# R7FA8M1AH register map
Vendor: Renesas; Series: RA8; File version: 1.2
CPU: CM85 r0p0, little endian, MPU, FPU, VTOR, 4 interrupt priority bits
Registers are 32-bit, read-write, reset 0x0 unless marked. A register's access mark holds for its fields unless they carry their own. Offsets are from the block's base; [hi:lo] are bit positions; {n}, {i} and the like mark numbered series; 'fields as' and 'values as' point back to an identical list.

## GLCDC — Graphics LCD Controller
Base 0x40342000
Same registers: GLCDC_NS 0x50342000
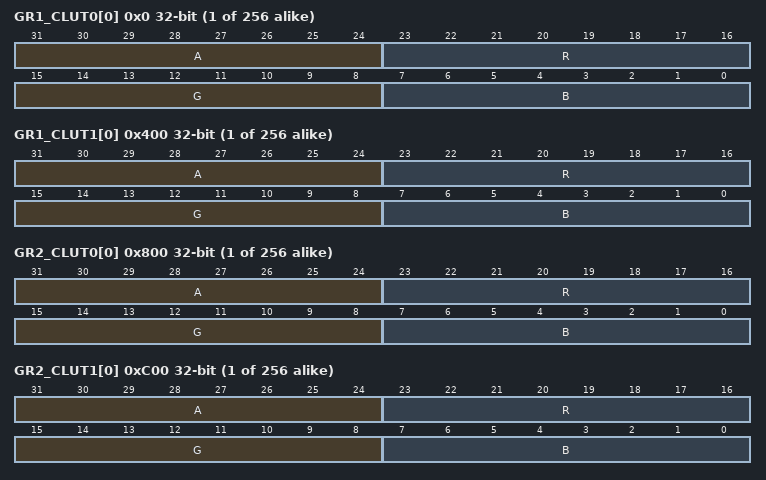
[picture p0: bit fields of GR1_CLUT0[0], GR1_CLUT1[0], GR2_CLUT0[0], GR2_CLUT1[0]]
{0x0+4i} GR1_CLUT0[{i}] (i=0..255) reset not defined — Color Palette 0 Plane for Graphics 1 Plane
  [31:24] A — Alpha Blending Value of Color Palette n Plane for Graphics m Plane
  [23:16] R — R Value of Color Palette n Plane for Graphics m Plane
  [15:8] G — G Value of Color Palette n Plane for Graphics m Plane
  [7:0] B — B Value of Color Palette n Plane for Graphics m Plane
{0x400+4i} GR1_CLUT1[{i}] (i=0..255) reset not defined — Color Palette 1 Plane for Graphics 1 Plane
  fields as GR1_CLUT0[0]
{0x800+4i} GR2_CLUT0[{i}] (i=0..255) reset not defined — Color Palette 0 Plane for Graphics 2 Plane
  fields as GR1_CLUT0[0]
{0xC00+4i} GR2_CLUT1[{i}] (i=0..255) reset not defined — Color Palette 1 Plane for Graphics 2 Plane
  fields as GR1_CLUT0[0]
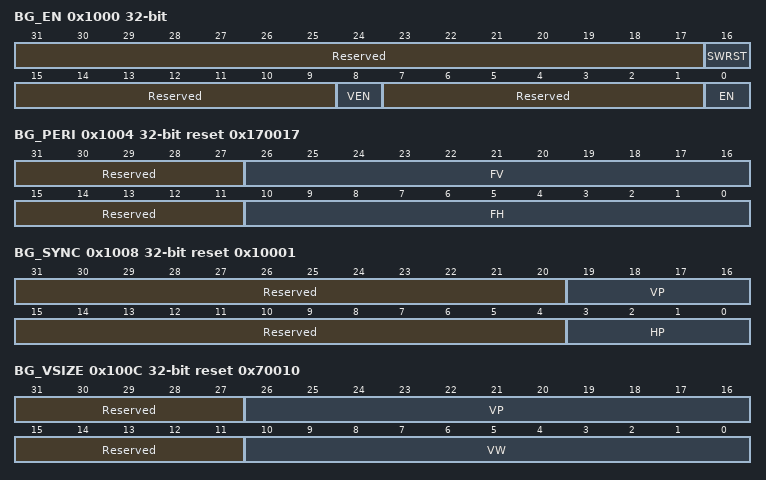
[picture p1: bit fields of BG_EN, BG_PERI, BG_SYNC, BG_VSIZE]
0x1000 BG_EN — Background Plane Setting Operation Control Register
  [31:17] Reserved — These bits are read as 000000000000000. The write value should be 000000000000000.
  [16] SWRST — Entire module SW reset control
    1=Releases the entire module from the SW reset state; 0=Places the entire module in the SW reset state
  [15:9] Reserved — These bits are read as 0000000. The write value should be 0000000.
  [8] VEN write-1-sets read-modifies — Control of LCDC internal register value reflection to internal operations
    1=Enables; 0=Disables(Cleared to 0 by an internal source)
  [7:1] Reserved — These bits are read as 0000000. The write value should be 0000000.
  [0] EN — Background plane generation module operation enable
    1=Enables operation; 0=Disables operation
0x1004 BG_PERI reset 0x170017 — Background Plane Setting Free-Running Period Register
  [31:27] Reserved — These bits are read as 00000. The write value should be 00000.
  [26:16] FV range 0x013..0x3FF — Background plane vertical synchronization signal period on the basis of line.
    other=FV (FV lines.The valid range is 0x013 to 0x3FF.)
  [15:11] Reserved — These bits are read as 00000. The write value should be 00000.
  [10:0] FH range 0x017..0x3FF — Background plane horizontal synchronization signal period on the basis of pixel clock (PXCLK).
    other=FH (FH lines. The valid range is 0x017 to 0x3FF.)
0x1008 BG_SYNC reset 0x10001 — Background Plane Setting Synchronization Position Register
  [31:20] Reserved — These bits are read as 000000000000. The write value should be 000000000000.
  [19:16] VP — Background plane vertical synchronization signal assertion position on the basis of line.
    0=Setting prohibited; other=others ((VP)th line)
  [15:4] Reserved — These bits are read as 000000000000. The write value should be 000000000000.
  [3:0] HP — Background plane horizontal synchronization signal assertion position on the basis of pixel clock (PXCLK).
    0=Setting prohibited; other=others ((HP)th line (pixels))
0x100C BG_VSIZE reset 0x70010 — Background Plane Setting Full Image Vertical Size Register
  [31:27] Reserved — These bits are read as 00000. The write value should be 00000.
  [26:16] VP range 0x0003..0x3EF — Background plane vertical valid pixel start position on the basis of line
    other=VP (VP lines. The valid range is 0x003 to 0x3EF.)
  [15:11] Reserved — These bits are read as 00000. The write value should be 00000.
  [10:0] VW range 0x0010..0x03FC — Background plane vertical valid pixel width on the basis of line
    other=VW (VW lines. The valid range is 0x010 to 0x3F0.)
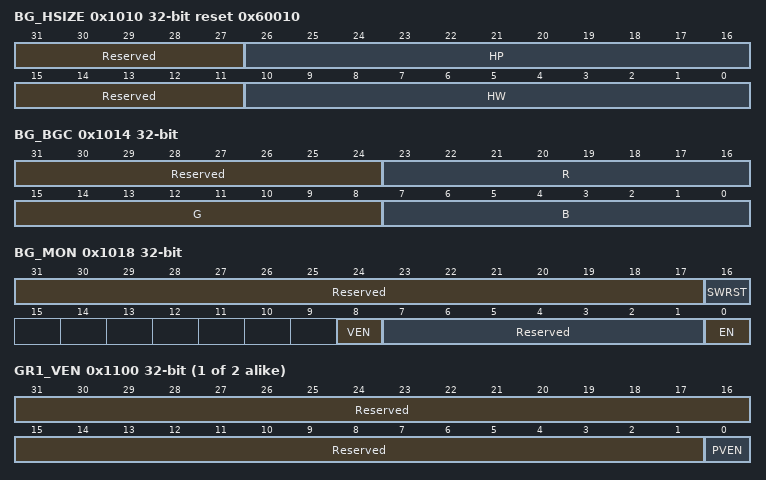
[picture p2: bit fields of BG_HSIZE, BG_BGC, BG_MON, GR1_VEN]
0x1010 BG_HSIZE reset 0x60010 — Background Plane Setting Full Image Horizontal Size Register
  [31:27] Reserved — These bits are read as 00000. The write value should be 00000.
  [26:16] HP range 0x006..0x3EE — Background plane horizontal valid pixel start position on the basis of pixel clock (PXCLK).
    other=HP (HP cycle(pixel). The valid range is 0x006 to 0x3EE.)
  [15:11] Reserved — These bits are read as 00000. The write value should be 00000.
  [10:0] HW range 0x010..0x3F8 — Background plane horizontall valid pixel width on the basis of pixel clock (PXCLK)Note: When serial RGB is selected as the output format for the output control block, add two to the horizontal enable signal width and set the resulting value to this field.
    other=HW (HW cycles. The valid range is 0x010 to 0x3F8.)
0x1014 BG_BGC — Background Plane Setting Background Color Register
  [31:24] Reserved — These bits are read as 00000000. The write value should be 00000000.
  [23:16] R — R value for background plane valid pixel area.Unsigned; 8-bit integer.
  [15:8] G — G value for background plane valid pixel areaUnsigned; 8-bit integer
  [7:0] B — B value for background plane valid pixel areaUnsigned; 8-bit integer
0x1018 BG_MON ro — Background Plane Setting Status Monitor Register
  [31:17] Reserved — These bits are read as 000000000000000.
  [16] SWRST — Entire module SW reset state monitor.
    1=The entire module is released from the SW reset state; 0=The entire module is in the SW reset state
  [8] VEN — Entire module internal operation reflection control signal monitor.The signal state for controlling reflection of the register values to the internal operations upon assertion of the vertical synchronization signal.
    1=The signal for controlling reflection of the register values to the internal operations upon assertion of the vertical synchronization signal is asserted; 0=The signal for controlling reflection of the register values to the internal operations upon assertion of the vertical synchronization signal is negated
  [7:1] Reserved — These bits are read as 0000000.
  [0] EN — Background plane generation module operation state monitor.
    1=Operation is in progress; 0=Operation is stopped
{0x1000+0x100*i} GR{i}_VEN (i=1..2) — Graphics {i} Register Update Control Register
  [31:1] Reserved — These bits are read as 0000000000000000000000000000000. The write value should be 0000000000000000000000000000000.
  [0] PVEN write-0-clears read-modifies — Control of graphics n module register value reflection to internal operations.Reflection of the register values to the internal operation at the assertion of the vertical synchronization signal (VS).
    1=Enables reflection of the register values to the internal operation at the assertion of the vertical synchronization signal (VS); 0=Disables reflection of the register values to the internal operation at the assertion of the vertical synchronization signal (VS)
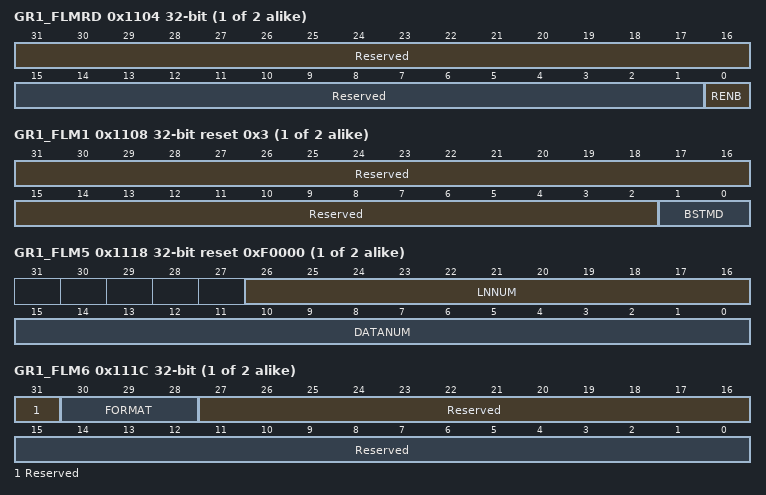
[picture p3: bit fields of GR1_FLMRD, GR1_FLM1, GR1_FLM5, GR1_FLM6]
{0x1004+0x100*i} GR{i}_FLMRD (i=1..2) — Graphics {i} Frame Buffer Read Control Register
  [31:16] Reserved — These bits are read as 0000000000000000. The write value should be 0000000000000000.
  [15:1] Reserved — These bits are read as 000000000000000. The write value should be 000000000000000.
  [0] RENB — Graphics data (frame buffer data) read enable.
    1=Enables reading; 0=Disables reading
{0x1008+0x100*i} GR{i}_FLM1 (i=1..2) reset 0x3 — Graphics {i} Frame Buffer Control Register 1
  [31:2] Reserved — These bits are read as 000000000000000000000000000000. The write value should be 000000000000000000000000000000.
  [1:0] BSTMD ro — Burst transfer control for graphics data (frame buffer data)access
    3=16-beat increment burst transfer (64-byte boundary); other=others (Setting prohibited.)
{0x100C+0x100*i} GR{i}_FLM2 (i=1..2) — Graphics {i} Frame Buffer Control Register 2
  [31:0] BASE — Base address for accessing graphics data (frame buffer data)Set the head address in the frame buffer where graphics data is to be stored. GRn_FLM2.BASE[5:0] should be fixed to 0 during 64-byte burst transfer.
{0x1010+0x100*i} GR{i}_FLM3 (i=1..2) — Graphics {i} Frame Buffer Control Register 3
  [31:16] LNOFF — Macro line offset address for accessing graphics data(frame buffer data)Signed; 16-bit integer
{0x1018+0x100*i} GR{i}_FLM5 (i=1..2) reset 0xF0000 — Graphics {i} Frame Buffer Control Register 5
  [26:16] LNNUM range 0x00F..0x3FF — Number of lines per frame for accessing graphics data (frame buffer data).
    other=LNNUM (LNNUM lines. The valid range is 0x00F to 0x3FF.)
  [15:0] DATANUM — Number of data transfer times per line for accessing graphics data (frame buffer data), where one transfer is defined as 16-beat burst access (64-byte boundary)
    other=DATAUM (DATAUM+1 times.)
{0x101C+0x100*i} GR{i}_FLM6 (i=1..2) — Graphics {i} Frame Buffer Control Register 6
  [31] Reserved — This bit is read as 0. The write value should be 0.
  [30:28] FORMAT — Data format for accessing graphics data (frame buffer data).
    7=CLUT11bit/pix); 6=CLUT4 (4 bits/pix); 5=CLUT8 (8 bits/pix); 4=ARGB8888 (32 bits/pix); 3=ARGB4444 (16 bits/pix); 2=ARGB1555 (16 bits/pix, 1 bit of A is LUT data); 1=RGB888 (32 bits/pix, 8 bits on the MSB side are invalid); 0=RGB565 (16 bits/pix); other=others (Setting prohibited.)
  [27:16] Reserved — These bits are read as 000000000000. The write value should be 000000000000.
  [15:0] Reserved — These bits are read as 0000000000000000. The write value should be 0000000000000000.
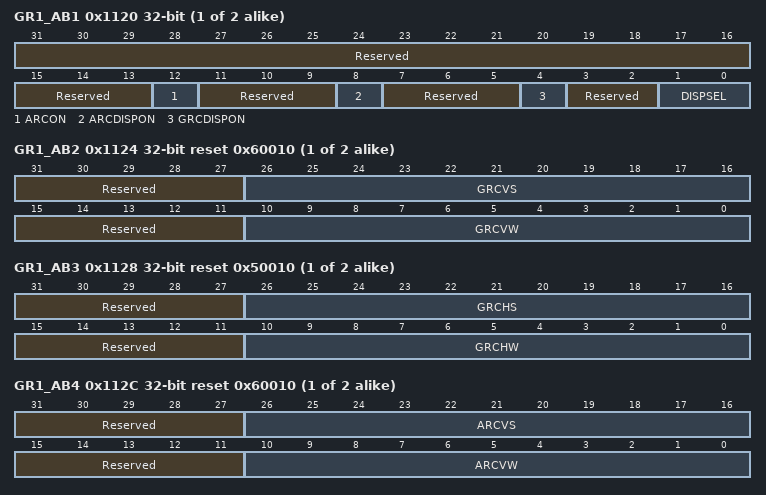
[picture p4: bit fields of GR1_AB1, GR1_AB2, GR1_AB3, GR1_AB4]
{0x1020+0x100*i} GR{i}_AB1 (i=1..2) — Graphics {i} Alpha Blending Control Register 1
  [31:13] Reserved — These bits are read as 0000000000000000000. The write value should be 0000000000000000000.
  [12] ARCON — Rectangular area alpha blending control.
    1=On; 0=Off
  [11:9] Reserved — These bits are read as 000. The write value should be 000.
  [8] ARCDISPON — Image area border display control for rectangular area alpha blending.
    1=Display on; 0=Display off
  [7:5] Reserved — These bits are read as 000. The write value should be 000.
  [4] GRCDISPON — Graphics image area border display control.
    1=Display on; 0=Display off
  [3:2] Reserved — These bits are read as 00. The write value should be 00.
  [1:0] DISPSEL — Graphics display plane control.
    3=Blended display of lower-layer graphics (input image from the previous stage) and current graphics (graphics data read from the AHB bus); 2=Current graphics display; 1=Lower-layer graphics display; 0=Background color display (value set by the GRn_BASE register)
{0x1024+0x100*i} GR{i}_AB2 (i=1..2) reset 0x60010 — Graphics {i} Alpha Blending Control Register 2
  [31:27] Reserved — These bits are read as 00000. The write value should be 00000.
  [26:16] GRCVS range 0x002..0x3EE — Vertical start position of graphics image area.
    other=GRCVS (GRCVS lines. The valid range is 0x002 to 0x3EE.)
  [15:11] Reserved — These bits are read as 00000. The write value should be 00000.
  [10:0] GRCVW range 0x010..0x3FC — Vertical width of graphics image area.
    other=GRCVW (GRCVW lines. The valid range is 0x010 to 0x3F0.)
{0x1028+0x100*i} GR{i}_AB3 (i=1..2) reset 0x50010 — Graphics {i} Alpha Blending Control Register 3
  [31:27] Reserved — These bits are read as 00000. The write value should be 00000.
  [26:16] GRCHS range 0x005..0x3ED — Horizontal start position of graphics image area.
    other=GRCHS (GRCHS lines. The valid range is 0x005 to 0x3ED.)
  [15:11] Reserved — These bits are read as 00000. The write value should be 00000.
  [10:0] GRCHW range 0x010..0x3F0 — Horizontal width of graphics image area.
    other=GRCHW (GRCHW pixels. The valid range is 0x010 to 0x3F0.)
{0x102C+0x100*i} GR{i}_AB4 (i=1..2) reset 0x60010 — Graphics {i} Alpha Blending Control Register 4
  [31:27] Reserved — These bits are read as 00000. The write value should be 00000.
  [26:16] ARCVS range 0x002..0x3EE — Vertical start position of rectangular area alpha blending image area
    other=ARCVS (ARCVS linels. The valid range is 0x002 to 0x3EE.)
  [15:11] Reserved — These bits are read as 00000. The write value should be 00000.
  [10:0] ARCVW range 0x001..0x3FC — Vertical width of rectangular area alpha blending image area.
    other=ARCVW (ARCVW linels. The valid range is 0x001 to 0x3F0.)
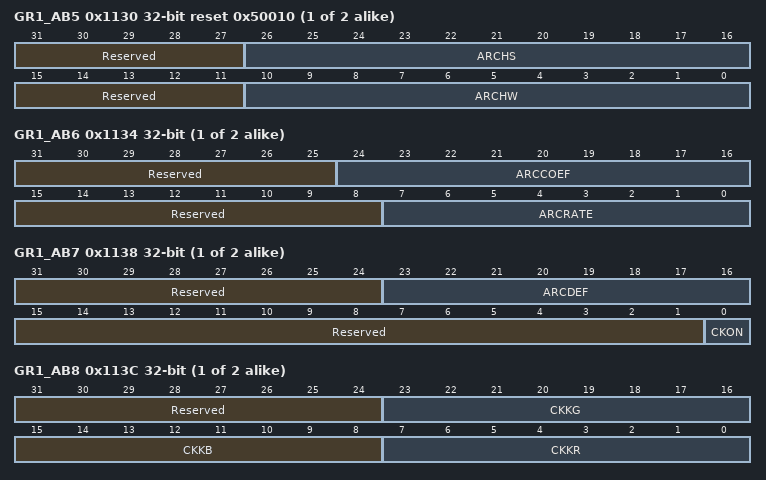
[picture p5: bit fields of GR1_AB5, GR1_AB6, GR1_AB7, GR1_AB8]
{0x1030+0x100*i} GR{i}_AB5 (i=1..2) reset 0x50010 — Graphics {i} Alpha Blending Control Register 5
  [31:27] Reserved — These bits are read as 00000. The write value should be 00000.
  [26:16] ARCHS range 0x005..0x3ED — Horizontal start position of rectangular area alpha blending image area.
    other=ARCHS (ARCHS pixel. The valid range is 0x005 to 0x3ED.)
  [15:11] Reserved — These bits are read as 00000. The write value should be 00000.
  [10:0] ARCHW range 0x001..0x3F8 — Horizontal width of rectangular area alpha blending image area.
    other=ARCHW (ARCHW pixels. The valid range is 0x001 to 0x3F0.)
{0x1034+0x100*i} GR{i}_AB6 (i=1..2) — Graphics {i} Alpha Blending Control Register 6
  [31:25] Reserved — These bits are read as 0000000. The write value should be 0000000.
  [24:16] ARCCOEF — Alpha coefficient for alpha blending in rectangular area (-255 to 255).[8]: Sign (0: addition, 1: subtraction)[7:0]: Variation (absolute value)
  [15:8] Reserved — These bits are read as 00000000. The write value should be 00000000.
  [7:0] ARCRATE — Frame rate for alpha blending in rectangular area.
    other=ARCRATE (ARCRATE+1 frames)
{0x1038+0x100*i} GR{i}_AB7 (i=1..2) — Graphics {i} Alpha Blending Control Register 7
  [31:24] Reserved — These bits are read as 00000000. The write value should be 00000000.
  [23:16] ARCDEF — Initial alpha value for alpha blending in rectangular area.
  [15:1] Reserved — These bits are read as 000000000000000. The write value should be 000000000000000.
  [0] CKON — RGB-index chroma-key processing control.
    1=Enables chroma-key processing; 0=Disables chroma-key processing
{0x103C+0x100*i} GR{i}_AB8 (i=1..2) — Graphics {i} Alpha Blending Control Register 8
  [31:24] Reserved — These bits are read as 00000000. The write value should be 00000000.
  [23:16] CKKG — G signal for RGB-index chroma-key processingUnsigned; 8 bits.
  [15:8] CKKB — B signal for RGB-index chroma-key processingUnsigned; 8 bits.
  [7:0] CKKR — R signal for RGB-index chroma-key processingUnsigned; 8 bits.
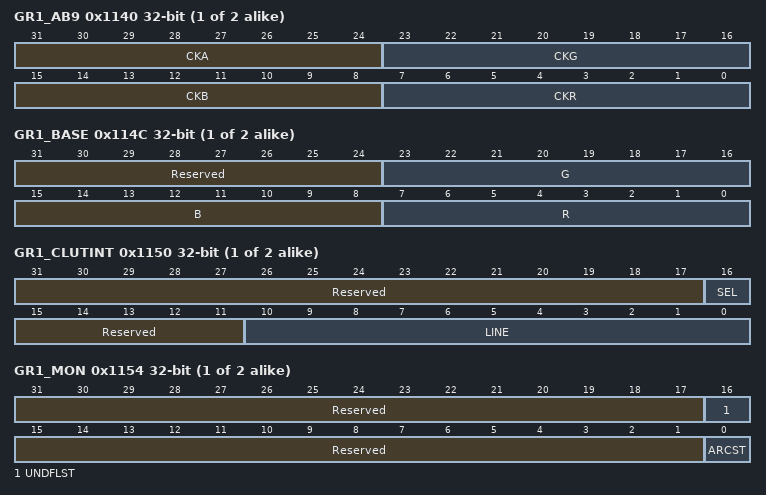
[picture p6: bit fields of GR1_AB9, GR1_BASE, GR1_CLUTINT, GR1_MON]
{0x1040+0x100*i} GR{i}_AB9 (i=1..2) — Graphics {i} Alpha Blending Control Register 9
  [31:24] CKA — A value after RGB-index chroma-key processing replacement.
  [23:16] CKG — G value after RGB-index chroma-key processing replacementUnsigned; 8 bits.
  [15:8] CKB — B value after RGB-index chroma-key processing replacementUnsigned; 8 bits.
  [7:0] CKR — R value after RGB-index chroma-key processing replacementUnsigned; 8 bits.
{0x104C+0x100*i} GR{i}_BASE (i=1..2) — Graphics {i} Background Color Control Register
  [31:24] Reserved — These bits are read as 00000000. The write value should be 00000000.
  [23:16] G — Background color G valueUnsigned; 8 bits
  [15:8] B — Background color B valueUnsigned; 8 bits
  [7:0] R — Background color R valueUnsigned; 8 bits
{0x1050+0x100*i} GR{i}_CLUTINT (i=1..2) — Graphics {i} CLUT Table Interrupt Control Register
  [31:17] Reserved — These bits are read as 000000000000000. The write value should be 000000000000000.
  [16] SEL — CLUT table control
    1=Uses CLUT1 plane for internal operations; 0=Uses CLUT0 plane for internal operations; other=others (Setting prohibited)
  [15:11] Reserved — These bits are read as 00000. The write value should be 00000.
  [10:0] LINE range 0x000..0x400 — Number of detection lines
    other=LINE (LINE+1 lines. The valid range is 0x000 to 0x400.)
{0x1054+0x100*i} GR{i}_MON (i=1..2) ro — Graphics {i} Status Monitor Register
  [31:17] Reserved — These bits are read as 000000000000000.
  [16] UNDFLST — Status monitor for underflow
    1=An underflow occurs in internal operations; 0=No underflow occurs in internal operations
  [15:1] Reserved — These bits are read as 000000000000000.
  [0] ARCST — Status monitor for alpha blending in rectangular area
    1=Fade-in/fade-out is in progress; 0=Fade-in/fade-out is not in progress
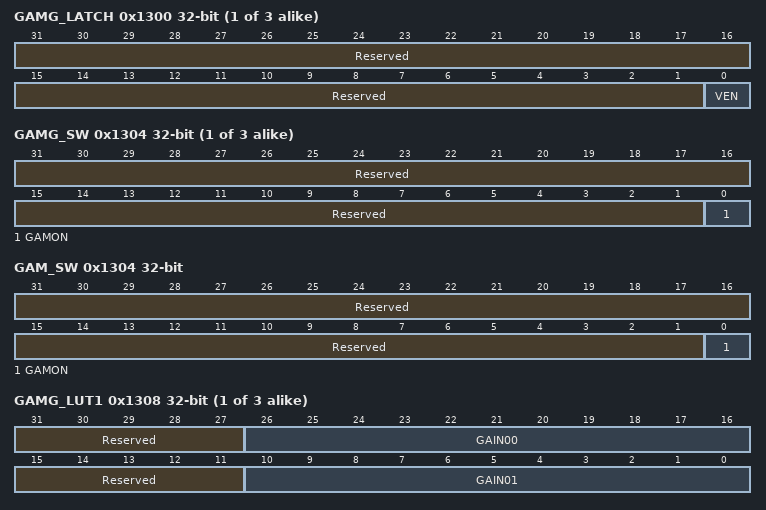
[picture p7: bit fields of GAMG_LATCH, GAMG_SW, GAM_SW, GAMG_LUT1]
0x1300 GAM{x}_LATCH (x=G,B,R; step 0x40) — Gamma {x} Register Update Control Register
  [31:1] Reserved — These bits are read as 0000000000000000000000000000000. The write value should be 0000000000000000000000000000000.
  [0] VEN write-0-clears read-modifies — Control of gamma correction x module register value reflection to internal operations.The register values to be reflected to the internal operations at the assertion of the vertical synchronization signal (VS).
    1=Enables the register values to be reflected to the internal operations at the assertion of the vertical synchronization signal (VS); 0=Disables the register values to be reflected to the internal operations at the assertion of the vertical synchronization signal (VS)
0x1304 GAM{x}_SW (x=G,B,R; step 0x40) — Gamma Correction Block Function Switch Register
  [31:1] Reserved — These bits are read as 0000000000000000000000000000000. The write value should be 0000000000000000000000000000000.
  [0] GAMON — Gamma correction on/off control
    1=Turns on gamma correction; 0=Turns off gamma correction
0x1304 GAM_SW — Gamma Correction Block Function Switch Register
  fields as GAM{x}_SW
0x1308 GAM{x}_LUT1 (x=G,B,R; step 0x40) — Gamma {x} Correction Block Table Setting Register 1
  [31:27] Reserved — These bits are read as 00000. The write value should be 00000.
  [26:16] GAIN00 — Gain value of area 0.Unsigned 11-bit fixed point.
    other=GAIN00 (GAIN00/1024)
  [15:11] Reserved — These bits are read as 00000. The write value should be 00000.
  [10:0] GAIN01 — Gain value of area 1Unsigned 11-bit fixed point
    other=GAIN01 (GAIN01/1024)
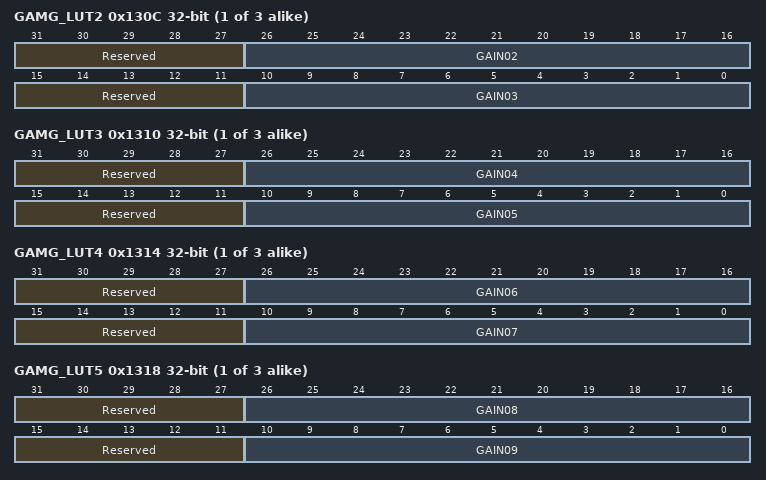
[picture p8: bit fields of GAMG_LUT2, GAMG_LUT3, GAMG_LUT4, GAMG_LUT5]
0x130C GAM{x}_LUT2 (x=G,B,R; step 0x40) — Gamma {x} Correction Block Table Setting Register 2
  [31:27] Reserved — These bits are read as 00000. The write value should be 00000.
  [26:16] GAIN02 — Gain value of area 2Unsigned 11-bit fixed point
    other=GAIN02 (GAIN02/1024)
  [15:11] Reserved — These bits are read as 00000. The write value should be 00000.
  [10:0] GAIN03 — Gain value of area 3Unsigned 11-bit fixed point
    other=GAIN03 (GAIN03/1024)
0x1310 GAM{x}_LUT3 (x=G,B,R; step 0x40) — Gamma {x} Correction Block Table Setting Register 3
  [31:27] Reserved — These bits are read as 00000. The write value should be 00000.
  [26:16] GAIN04 — Gain value of area 4Unsigned 11-bit fixed point
    other=GAIN04 (GAIN04/1024)
  [15:11] Reserved — These bits are read as 00000. The write value should be 00000.
  [10:0] GAIN05 — Gain value of area 5Unsigned 11-bit fixed point
    other=GAIN05 (GAIN05/1024)
0x1314 GAM{x}_LUT4 (x=G,B,R; step 0x40) — Gamma {x} Correction Block Table Setting Register 4
  [31:27] Reserved — These bits are read as 00000. The write value should be 00000.
  [26:16] GAIN06 — Gain value of area 6Unsigned 11-bit fixed point
    other=GAIN06 (GAIN06/1024)
  [15:11] Reserved — These bits are read as 00000. The write value should be 00000.
  [10:0] GAIN07 — Gain value of area 7Unsigned 11-bit fixed point
    other=GAIN07 (GAIN07/1024)
0x1318 GAM{x}_LUT5 (x=G,B,R; step 0x40) — Gamma {x} Correction Block Table Setting Register 5
  [31:27] Reserved — These bits are read as 00000. The write value should be 00000.
  [26:16] GAIN08 — Gain value of area 8Unsigned 11-bit fixed point
    other=GAIN08 (GAIN08/1024)
  [15:11] Reserved — These bits are read as 00000. The write value should be 00000.
  [10:0] GAIN09 — Gain value of area 9Unsigned 11-bit fixed point
    other=GAIN09 (GAIN09/1024)
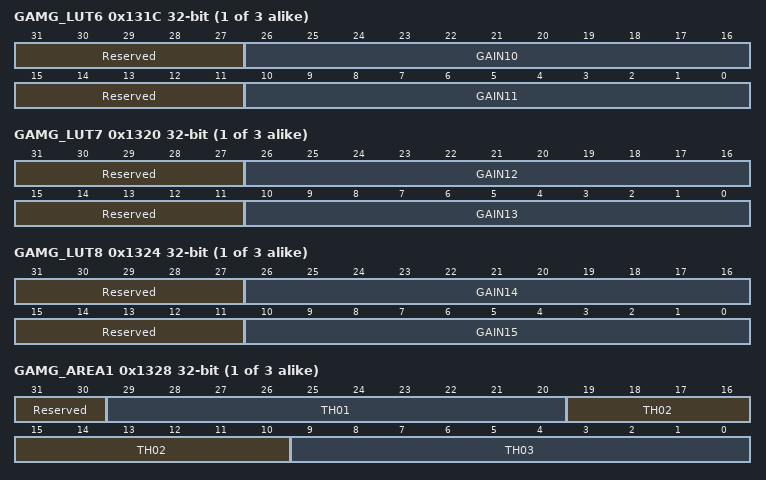
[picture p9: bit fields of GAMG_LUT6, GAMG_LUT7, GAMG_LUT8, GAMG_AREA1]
0x131C GAM{x}_LUT6 (x=G,B,R; step 0x40) — Gamma {x} Correction Block Table Setting Register 6
  [31:27] Reserved — These bits are read as 00000. The write value should be 00000.
  [26:16] GAIN10 — Gain value of area 10Unsigned 11-bit fixed point
    other=GAIN10 (GAIN10/1024)
  [15:11] Reserved — These bits are read as 00000. The write value should be 00000.
  [10:0] GAIN11 — Gain value of area 11Unsigned 11-bit fixed point
    other=GAIN11 (GAIN11/1024)
0x1320 GAM{x}_LUT7 (x=G,B,R; step 0x40) — Gamma {x} Correction Block Table Setting Register 7
  [31:27] Reserved — These bits are read as 00000. The write value should be 00000.
  [26:16] GAIN12 — Gain value of area 12Unsigned 11-bit fixed point
    other=GAIN12 (GAIN12/1024)
  [15:11] Reserved — These bits are read as 00000. The write value should be 00000.
  [10:0] GAIN13 — Gain value of area 13Unsigned 11-bit fixed point
    other=GAIN13 (GAIN13/1024)
0x1324 GAM{x}_LUT8 (x=G,B,R; step 0x40) — Gamma {x} Correction Block Table Setting Register 8
  [31:27] Reserved — These bits are read as 00000. The write value should be 00000.
  [26:16] GAIN14 — Gain value of area 14Unsigned 11-bit fixed point
    other=GAIN14 (GAIN14/1024)
  [15:11] Reserved — These bits are read as 00000. The write value should be 00000.
  [10:0] GAIN15 — Gain value of area 15Unsigned 11-bit fixed point
    other=GAIN15 (GAIN15/1024)
0x1328 GAM{x}_AREA1 (x=G,B,R; step 0x40) — Gamma {x} Correction Block Area Setting Register 1
  [31:30] Reserved — These bits are read as 00. The write value should be 00.
  [29:20] TH01 — Start threshold of area 1Unsigned 10-bit integer
  [19:10] TH02 — Start threshold of area 2Unsigned 10-bit integer
  [9:0] TH03 — Start threshold of area 3Unsigned 10-bit integer
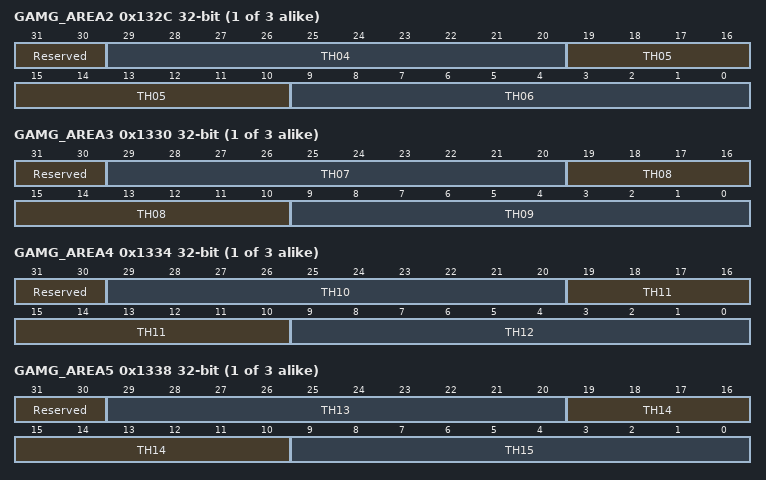
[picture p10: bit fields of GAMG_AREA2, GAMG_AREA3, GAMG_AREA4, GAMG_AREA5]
0x132C GAM{x}_AREA2 (x=G,B,R; step 0x40) — Gamma {x} Correction Block Area Setting Register 2
  [31:30] Reserved — These bits are read as 00. The write value should be 00.
  [29:20] TH04 — Start threshold of area 4Unsigned 10-bit integer
  [19:10] TH05 — Start threshold of area 5Unsigned 10-bit integer
  [9:0] TH06 — Start threshold of area 6Unsigned 10-bit integer
0x1330 GAM{x}_AREA3 (x=G,B,R; step 0x40) — Gamma {x} Correction Block Area Setting Register 3
  [31:30] Reserved — These bits are read as 00. The write value should be 00.
  [29:20] TH07 — Start threshold of area 7Unsigned 10-bit integer
  [19:10] TH08 — Start threshold of area 8Unsigned 10-bit integer
  [9:0] TH09 — Start threshold of area 9Unsigned 10-bit integer
0x1334 GAM{x}_AREA4 (x=G,B,R; step 0x40) — Gamma {x} Correction Block Area Setting Register 4
  [31:30] Reserved — These bits are read as 00. The write value should be 00.
  [29:20] TH10 — Start threshold of area 10Unsigned 10-bit integer
  [19:10] TH11 — Start threshold of area 11Unsigned 10-bit integer
  [9:0] TH12 — Start threshold of area 12Unsigned 10-bit integer
0x1338 GAM{x}_AREA5 (x=G,B,R; step 0x40) — Gamma {x} Correction Block Area Setting Register 5
  [31:30] Reserved — These bits are read as 00. The write value should be 00.
  [29:20] TH13 — Start threshold of area 13Unsigned 10-bit integer
  [19:10] TH14 — Start threshold of area 14Unsigned 10-bit integer
  [9:0] TH15 — Start threshold of area 15Unsigned 10-bit integer
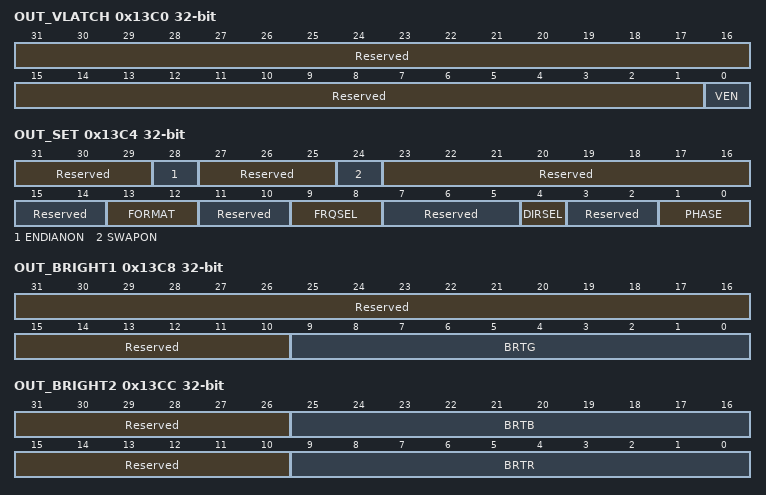
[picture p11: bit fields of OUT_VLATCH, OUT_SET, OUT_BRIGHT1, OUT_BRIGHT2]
0x13C0 OUT_VLATCH — Output Control Block Register Update Control Register
  [31:1] Reserved — These bits are read as 0000000000000000000000000000000. The write value should be 0000000000000000000000000000000.
  [0] VEN write-0-clears read-modifies — Control of output control module register value reflection to internal operations.The register values to be reflected to the internal operations at the assertion of the vertical synchronization signal (VS).
    values as GAM{x}_LATCH.VEN
0x13C4 OUT_SET — Output Control Block Output Interface Register
  [31:29] Reserved — These bits are read as 000. The write value should be 000.
  [28] ENDIANON — Bit endian change control
    1=Ascending order (big endian); 0=Descending order (little endian)
  [27:25] Reserved — These bits are read as 000. The write value should be 000.
  [24] SWAPON — Pixel order control
    1=In the order of BGR; 0=In the order of RGB
  [23:16] Reserved — These bits are read as 00000000. The write value should be 00000000.
  [15:14] Reserved — These bits are read as 00. The write value should be 00.
  [13:12] FORMAT — Output format select
    3=Serial RGB; select RGB888 as dither output format; 2=RGB565; select RGB565 as dither output format; 1=RGB666; select RGB666 as dither output format; 0=RGB888; select RGB888 as dither output format
  [11:10] Reserved — These bits are read as 00. The write value should be 00.
  [9:8] FRQSEL — Clock frequency division control
    3=Setting prohibited; 2=Quarter frequency (serial RGB); 1=Setting prohibited; 0=No frequency division, parallel RGB
  [7:5] Reserved — These bits are read as 000. The write value should be 000.
  [4] DIRSEL — Invalid data position control in serial RGB format
    1=Invalid data is output prior to valid (RGB) data; 0=Invalid data is output following valid (RGB) data
  [3:2] Reserved — These bits are read as 00. The write value should be 00.
  [1:0] PHASE — Data delay in serial RGB format (based on OUTCLK)
    3=3 cycles; 2=2 cycles; 1=1 cycle; 0=0 cycle
0x13C8 OUT_BRIGHT1 — Output Control Block Brightness Correction Register 1
  [31:10] Reserved — These bits are read as 0000000000000000000000. The write value should be 0000000000000000000000.
  [9:0] BRTG — Brightness (DC) adjustment of G signalUnsigned; 10 bits; +512 with offset; integer
0x13CC OUT_BRIGHT2 — Output Control Block Brightness Correction Register 2
  [31:26] Reserved — These bits are read as 000000. The write value should be 000000.
  [25:16] BRTB — Brightness (DC) adjustment of B signalUnsigned; 10 bits; +512 with offset; integer
  [15:10] Reserved — These bits are read as 000000. The write value should be 000000.
  [9:0] BRTR — Brightness (DC) adjustment of R signalUnsigned; 10 bits; +512 with offset; integer
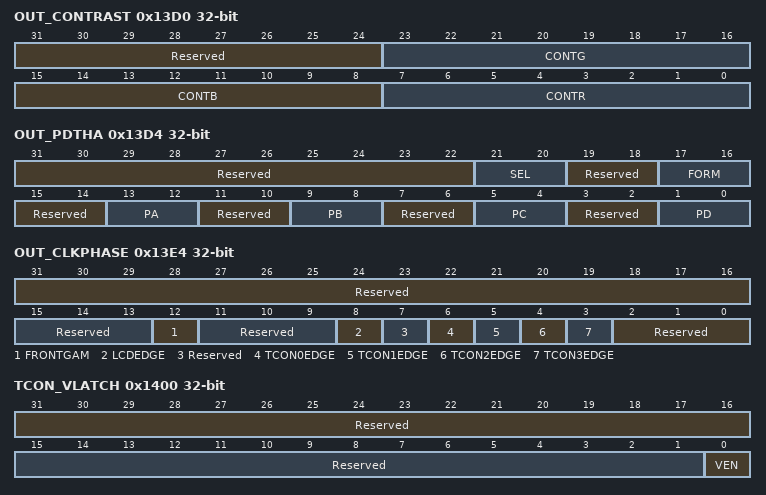
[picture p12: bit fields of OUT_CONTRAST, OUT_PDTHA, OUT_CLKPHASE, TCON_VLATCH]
0x13D0 OUT_CONTRAST — Output Control Block Contrast Correction Register
  [31:24] Reserved — These bits are read as 00000000. The write value should be 00000000.
  [23:16] CONTG — Contrast (GAIN) adjustment of G signalUnsigned; 8 bits fixed point.
    other=CONTG (CONTG/128)
  [15:8] CONTB — Contrast (GAIN) adjustment of B signalUnsigned; 8 bits fixed point
    other=CONTB (CONTB/128)
  [7:0] CONTR — Contrast (GAIN) adjustment of R signalUnsigned; 8 bits fixed point
    other=CONTR (CONTR/128)
0x13D4 OUT_PDTHA — Output Control Block Panel Dither Correction Register
  [31:22] Reserved — These bits are read as 0000000000. The write value should be 0000000000.
  [21:20] SEL — Operation mode
    3=Setting prohibited; 2=2x2 pattern dither; 1=Round-off; 0=Truncate
  [19:18] Reserved — These bits are read as 00. The write value should be 00.
  [17:16] FORM — Output format select
    3=Setting prohibited; 2=RGB565; select RGB565 as output interface format; 1=RGB666; select RGB666 as output interface format; 0=RGB888; select RGB888 or serial RGB as output interface format
  [15:14] Reserved — These bits are read as 00. The write value should be 00.
  [13:12] PA — Pattern value (A) of 2 x 2 pattern ditherUnsigned 2-bit integer
  [11:10] Reserved — These bits are read as 00. The write value should be 00.
  [9:8] PB — Pattern value (B) of 2 x 2 pattern ditherUnsigned 2-bit integer
  [7:6] Reserved — These bits are read as 00. The write value should be 00.
  [5:4] PC — Pattern value (C) of 2 x 2 pattern ditherUnsigned 2-bit integer
  [3:2] Reserved — These bits are read as 00. The write value should be 00.
  [1:0] PD — Pattern value (D) of 2 x 2 pattern ditherUnsigned 2-bit integer
0x13E4 OUT_CLKPHASE — Output Control Block Output Phase Control Register
  [31:16] Reserved — These bits are read as 0000000000000000. The write value should be 0000000000000000.
  [15:13] Reserved — These bits are read as 000. The write value should be 000.
  [12] FRONTGAM — Correction control
    1=Gamma correction is followed by brightness/contrast correction; 0=Brightness/contrast correction is followed by gamma correction
  [11:9] Reserved — These bits are read as 000. The write value should be 000.
  [8] LCDEDGE — LCD_DATA Output Phase Control
    0=In synchronization with the rising edge of LCD_CLK; 1=In synchronization with the falling edge of LCD_CLK
  [7] Reserved — This bit is read as 0. The write value should be 0.
  [6-n] TCON{n}EDGE (n=0..3) — LCD_TCON{n} Output Phase Control
    1=In synchronization with the falling edge of LCD_CLK; 0=In synchronization with the rising edge of LCD_CLK
  [2:0] Reserved — These bits are read as 000. The write value should be 000.
0x1400 TCON_VLATCH
  [31:16] Reserved — These bits are read as 0000000000000000. The write value should be 0000000000000000.
  [15:1] Reserved — These bits are read as 000000000000000. The write value should be 000000000000000.
  [0] VEN
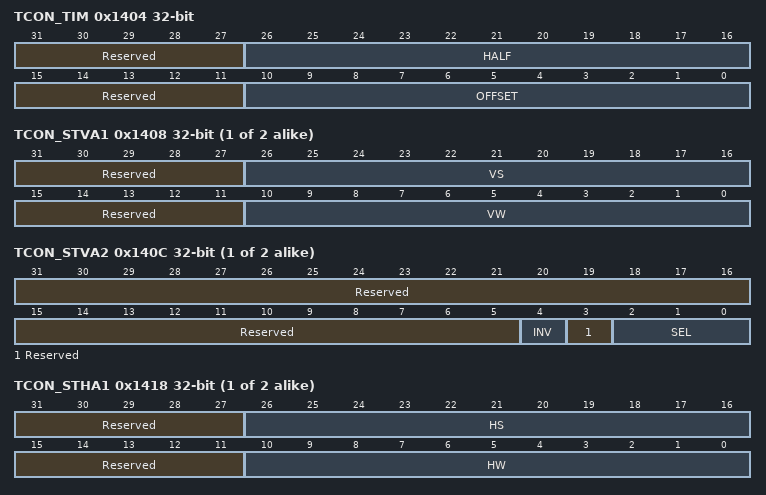
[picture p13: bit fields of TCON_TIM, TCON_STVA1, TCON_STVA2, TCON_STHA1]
0x1404 TCON_TIM — TCON Reference Timing Setting Register
  [31:27] Reserved — These bits are read as 00000. The write value should be 00000.
  [26:16] HALF range 0x000..0x3FF — Vertical synchronization signal generation change timing Sets the delay from the assertion of the internal horizontal synchronization signal in terms of pixels.
    other=HALF (HALF pixels. The valid range is 0x000 to 0x3FF.)
  [15:11] Reserved — These bits are read as 00000. The write value should be 00000.
  [10:0] OFFSET range 0x000..0x3FF — Horizontal synchronization signal generation reference timingSets the offset from the assertion of the internal horizontal synchronization signal in terms of pixels.
    other=OFFSET (OFFSET+1 pixels. The valid range is 0x000 to 0x3FF.)
0x1408 TCON_STV{x}1 (x=A,B; step 0x8) — TCON Vertical Timing Setting Register {x}1
  [31:27] Reserved — These bits are read as 00000. The write value should be 00000.
  [26:16] VS range 0x000..0x7FF — STVx1 first change timing
    other=VS (VS pixels. The valid range is 0x000 to 0x3FF.)
  [15:11] Reserved — These bits are read as 00000. The write value should be 00000.
  [10:0] VW range 0x000..0x7FF — STVx1 second change timingSets the signal assertion width.
    other=VW (VW pixels. The valid range is 0x000 to 0x3FF.)
0x140C TCON_STV{x}2 (x=A,B; step 0x8) — TCON Vertical Timing Setting Register {x}2
  [31:5] Reserved — These bits are read as 000000000000000000000000000. The write value should be 000000000000000000000000000.
  [4] INV — STVx signal polarity inversion control
    1=Inverted; 0=Not inverted
  [3] Reserved — This bit is read as 0. The write value should be 0.
  [2:0] SEL — Output signal select control for VSOUT (controlled by TCON_STVA2 register)/VEOUT (controlled by the TCON_STVB2 register) pin
    7=DE; 6=Setting prohibited; 5=Setting prohibited; 4=Setting prohibited; 3=STHB; 2=STHA; 1=STVB; 0=STVA
0x1418 TCON_STH{x}1 (x=A,B; step 0x8) — TCON Horizontal Timing Setting Register STH{x}1
  [31:27] Reserved — These bits are read as 00000. The write value should be 00000.
  [26:16] HS range 0x000..0x3FF — STHx1 first change timing
    other=HS (HS lines. The valid range is 0x000 to 0x3FF.)
  [15:11] Reserved — These bits are read as 00000. The write value should be 00000.
  [10:0] HW range 0x000..0x3FF — STHx1 second change timing.Sets the signal assertion width.
    other=HW (HW pixels. The valid range is 0x000 to 0x3FF.)
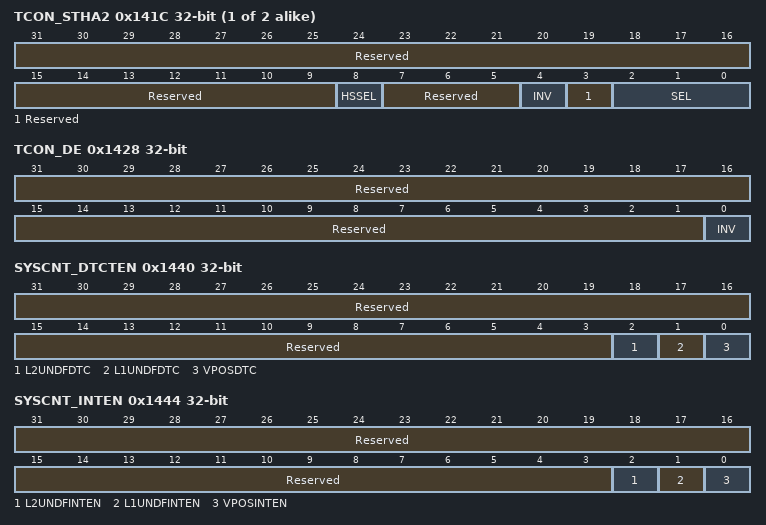
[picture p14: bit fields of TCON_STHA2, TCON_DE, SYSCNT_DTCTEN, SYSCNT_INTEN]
0x141C TCON_STH{x}2 (x=A,B; step 0x8) — TCON Horizontal Timing Setting Register STH{x}2
  [31:9] Reserved — These bits are read as 00000000000000000000000. The write value should be 00000000000000000000000.
  [8] HSSEL — STHx signal generation reference timing control.
    1=Reference timing is the offset set with the TCON_TIM.OFFSET[10:0] (horizontal synchronization generation reference timing) field; 0=Reference timing is the input horizontal synchronization signal (HSIN)
  [7:5] Reserved — These bits are read as 000. The write value should be 000.
  [4] INV — STVx signal polarity inversion control.
    1=Inverted; 0=Not inverted
  [3] Reserved — This bit is read as 0. The write value should be 0.
  [2:0] SEL — Output signal select control for LCD_TCON2 (controlled by TCON_STHA2 register)/LCD_TCON3 (controlled by the TCON_STHB2 register) pin.
    values as TCON_STV{x}2.SEL
0x1428 TCON_DE — TCON Data Enable Polarity Setting Register
  [31:1] Reserved — These bits are read as 0000000000000000000000000000000. The write value should be 0000000000000000000000000000000.
  [0] INV — DE signal polarity inversion control.
    1=Inverted; 0=Not inverted
0x1440 SYSCNT_DTCTEN — System Control Block State Detection Control Register
  [31:3] Reserved — These bits are read as 00000000000000000000000000000. The write value should be 00000000000000000000000000000.
  [2] L2UNDFDTC — Graphics 2 underflow detection control
    1=Enables detection; 0=Disables detection
  [1] L1UNDFDTC — Graphics 1 underflow detection control
    1=Enables detection; 0=Disables detection
  [0] VPOSDTC — Specified line detection control
    1=Enables detection; 0=Disables detection
0x1444 SYSCNT_INTEN — System Control Block Interrupt Request Enable Control Register
  [31:3] Reserved — These bits are read as 00000000000000000000000000000. The write value should be 00000000000000000000000000000.
  [2] L2UNDFINTEN — Interrupt request signal GLCDC_L2UNDF enable control.
    1=Enables GLCDC_L2UNDF output; 0=Disables GLCDC_L2UNDF output
  [1] L1UNDFINTEN — Interrupt request signal GLCDC_L1UNDF enable control.
    1=Enables GLCDC_L1UNDF output; 0=Disables GLCDC_L1UNDF output
  [0] VPOSINTEN — Interrupt request signal GLCDC_VPOS enable control.
    1=Enables GLCDC_VPOS output; 0=Disables GLCDC_VPOS output
0x1448 SYSCNT_STCLR — System Control Block Status Clear Register
  [31:3] Reserved — These bits are read as 00000000000000000000000000000. The write value should be 00000000000000000000000000000.
  [2] L2UNDFCLR — Graphics 2 underflow detection flag clear field
    1=Clears the graphics 2 underflow detection flag; 0=No operation
  [1] L1UNDFCLR — Graphics 1 underflow detection flag clear field
    1=Clears the graphics 1 underflow detection flag; 0=No operation
  [0] VPOSCLR — Graphics 2 specified line detection flag clear field
    1=Clears the specified line detection flag; 0=No operation
0x144C SYSCNT_STMON ro — System Control Block Status Monitor Register
  [31:3] Reserved — These bits are read as 00000000000000000000000000000.
  [2] L2UNDF — Graphics 2 underflow detection flag
    1=An underflow has been detected in graphics 2; 0=No underflow has been detected in graphics 2
  [1] L1UNDF — Graphics 1 underflow detection flag
    1=An underflow has been detected in graphics 1; 0=No underflow has been detected in graphics 1
  [0] VPOS — Graphics 2 specified line detection flag
    1=A specified line notification has been detected in graphics 2; 0=No specified line notification has been detected in graphics 2
0x1450 SYSCNT_PANEL_CLK reset 0x1100000 — System Control Block Version and Panel Clock Control Register
  [31:16] VER ro — Version informationVersion information of the GLCD
  [15:13] Reserved — These bits are read as 000. The write value should be 000.
  [12] PIXSEL — Pixel clock select control.Must be set to the same value as OUT_SET.FRQSEL[1].
    0=No frequency division, parallel RGB; 1=Quarter frequency,serial RGB
  [11:9] Reserved — These bits are read as 000. The write value should be 000.
  [8] CLKSEL — Panel clock supply source select
    0=External clock select; 1=PLL output select
  [7] Reserved — This bit is read as 0. The write value should be 0.
  [6] CLKEN — Panel clock output enable controlNote: Before changing the PIXSEL,CLKSEL or DCDR bit, this bit must be set to 0.
    0=Disable panel clock output; 1=Enable panel clock output
  [5:0] DCDR — Clock division ratio setting controlRefer toTable 2.7.1 for details about setting value.Note: Settings that are not listed in table 2.7.1 are prohibited.
